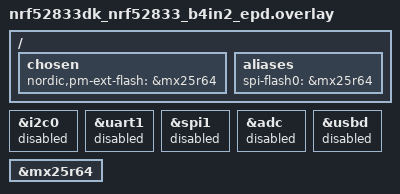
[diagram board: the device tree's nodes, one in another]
/*
 * Copyright (c) 2023 Nordic Semiconductor ASA
 *
 * SPDX-License-Identifier: Apache-2.0
 */

#include "waveshare_epaper_WFT0420CZ15.dtsi"
#include "waveshare_epaper_common_b.dtsi"

/ {
	chosen {
		nordic,pm-ext-flash = &mx25r64;
	};


	aliases {
		spi-flash0 = &mx25r64;
	};
};

&i2c0 {
	status = "disabled";
};
&uart1 {
	status = "disabled";
};
&spi1 {
	status = "disabled";
};
&adc {
	status = "disabled";
};
&usbd {
	status = "disabled";
};

&mx25r64 {
	status = "okay";
};

